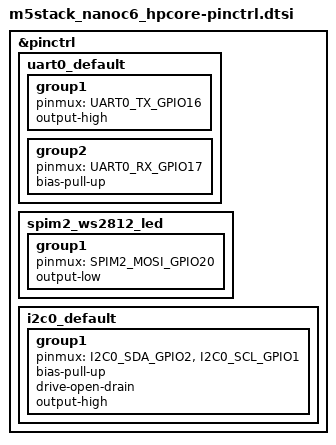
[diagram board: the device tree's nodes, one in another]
/*
 * Copyright (c) 2023 Espressif Systems (Shanghai) Co., Ltd.
 *
 * SPDX-License-Identifier: Apache-2.0
 */

#include <zephyr/dt-bindings/pinctrl/esp-pinctrl-common.h>
#include <dt-bindings/pinctrl/esp32c6-pinctrl.h>
#include <zephyr/dt-bindings/pinctrl/esp32c6-gpio-sigmap.h>

&pinctrl {
	uart0_default: uart0_default {
		group1 {
			pinmux = <UART0_TX_GPIO16>;
			output-high;
		};

		group2 {
			pinmux = <UART0_RX_GPIO17>;
			bias-pull-up;
		};
	};

	spim2_ws2812_led: spim2_ws2812_led {
		group1 {
			pinmux = <SPIM2_MOSI_GPIO20>;
			output-low;
		};
	};

	i2c0_default: i2c0_default {
		group1 {
			pinmux = <I2C0_SDA_GPIO2>,
				 <I2C0_SCL_GPIO1>;
			bias-pull-up;
			drive-open-drain;
			output-high;
		};
	};
};
